# AT32F403Axx_v2 register map
Vendor: Keil; Series: AT32F403A; File version: 1.0
CPU: CM4 r0p1, little endian, no MPU, FPU, 4 interrupt priority bits
Registers are 32-bit, read-write, reset 0x0 unless marked. A register's access mark holds for its fields unless they carry their own. Offsets are from the block's base; [hi:lo] are bit positions.

## SPI1 — Serial peripheral interface
Base 0x40013000
Same registers: SPI2 0x40003800, SPI3 0x40003C00, SPI4 0x40004000, I2S2_EXT 0x40016C00, I2S3_EXT 0x40017000
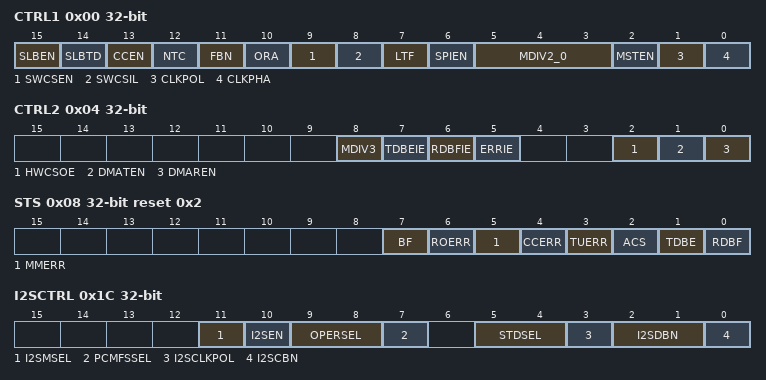
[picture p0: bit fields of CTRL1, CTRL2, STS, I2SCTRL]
0x00 CTRL1 — control register 1
  [15] SLBEN — Single line bidirectional half-duplex enable
  [14] SLBTD — Single line bidirectional half-duplex transmission direction
  [13] CCEN — CRC calculation enable
  [12] NTC — Next transmission CRC
  [11] FBN — frame bit num
  [10] ORA — Only receive active
  [9] SWCSEN — Software CS enable
  [8] SWCSIL — Software CS internal level
  [7] LTF — LSB transmit first
  [6] SPIEN — SPI enable
  [5:3] MDIV2_0 — Master clock frequency division bit2-0
  [2] MSTEN — Master enable
  [1] CLKPOL — Clock polarity
  [0] CLKPHA — Clock phase
0x04 CTRL2 — control register 2
  [8] MDIV3 — Master clock frequency division bit3
  [7] TDBEIE — Transmit data buffer empty interrupt enable
  [6] RDBFIE — Receive data buffer full interrupt enable
  [5] ERRIE — Error interrupt enable
  [2] HWCSOE — Hardware CS output enable
  [1] DMATEN — DMA transmit enable
  [0] DMAREN — DMA receive enable
0x08 STS reset 0x2 — status register
  [7] BF ro — Busy flag
  [6] ROERR ro — Receiver overflow error
  [5] MMERR ro — Master mode error
  [4] CCERR — CRC calculation error
  [3] TUERR ro — Transmitter underload error
  [2] ACS ro — Audio channel state
  [1] TDBE ro — Transmit data buffer empty
  [0] RDBF ro — Receive data buffer full
0x0C DT — data register
  [15:0] DT — Data value
0x10 CPOLY reset 0x7 — CRC polynomial register
  [15:0] CPOLY — CRC polynomial
0x14 RCRC ro — Receive CRC register
  [15:0] RCRC — Receive CRC
0x18 TCRC ro — Transmit CRC register
  [15:0] TCRC — Transmit CRC
0x1C I2SCTRL — I2S control register
  [11] I2SMSEL — I2S mode select
  [10] I2SEN — I2S Enable
  [9:8] OPERSEL — I2S operation select
  [7] PCMFSSEL — PCM frame synchronization select
  [5:4] STDSEL — I2S standard select
  [3] I2SCLKPOL — I2S clock polarity
  [2:1] I2SDBN — I2S data bit num
  [0] I2SCBN — I2S channel bit num
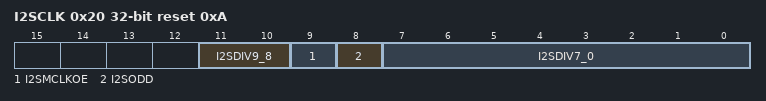
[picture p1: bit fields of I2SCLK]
0x20 I2SCLK reset 0xA — I2S clock register
  [11:10] I2SDIV9_8 — I2S division bit9 and bit8
  [9] I2SMCLKOE — I2S master clock output enable
  [8] I2SODD — Odd result for I2S division
  [7:0] I2SDIV7_0 — I2S division bit7 to bit0

## USART1 — Universal synchronous asynchronous receiver transmitter
Base 0x40013800
Same registers: USART2 0x40004400, USART3 0x40004800, UART4 0x40004C00, UART5 0x40005000, USART6 0x40016000, UART7 0x40016400, UART8 0x40016800
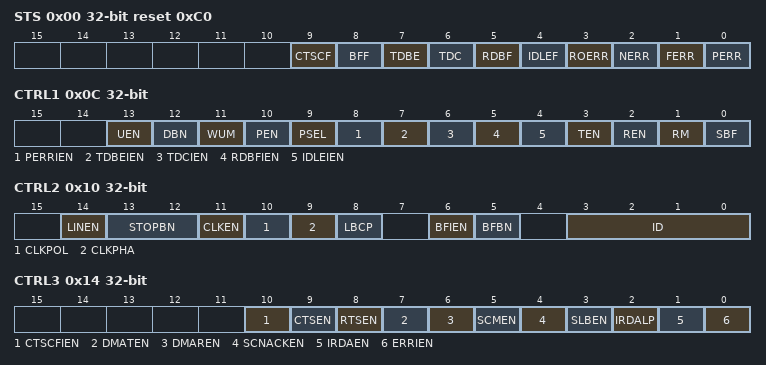
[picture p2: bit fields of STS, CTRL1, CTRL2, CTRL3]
0x00 STS reset 0xC0 — Status register
  [9] CTSCF — CTS change flag
  [8] BFF — Break frame flag
  [7] TDBE ro — Transmit data buffer empty
  [6] TDC — Transmit data complete
  [5] RDBF — Receive data buffer full
  [4] IDLEF ro — IDLE flag
  [3] ROERR ro — Receiver overflow error
  [2] NERR ro — Noise error
  [1] FERR ro — Framing error
  [0] PERR ro — Parity error
0x04 DT — Data register
  [8:0] DT — Data value
0x08 BAUDR — Baud rate register
  [15:0] DIV — Division
0x0C CTRL1 — Control register 1
  [13] UEN — USART enable
  [12] DBN — Data bit num
  [11] WUM — Wake up mode
  [10] PEN — Parity enable
  [9] PSEL — Parity selection
  [8] PERRIEN — PERR interrupt enable
  [7] TDBEIEN — TDBE interrupt enable
  [6] TDCIEN — TDC interrupt enable
  [5] RDBFIEN — RDBF interrupt enable
  [4] IDLEIEN — IDLE interrupt enable
  [3] TEN — Transmitter enable
  [2] REN — Receiver enable
  [1] RM — Receiver mute
  [0] SBF — Send break frame
0x10 CTRL2 — Control register 2
  [14] LINEN — LIN mode enable
  [13:12] STOPBN — STOP bit num
  [11] CLKEN — Clock enable
  [10] CLKPOL — Clock polarity
  [9] CLKPHA — Clock phase
  [8] LBCP — Last bit clock pulse
  [6] BFIEN — Break frame interrupt enable
  [5] BFBN — Break frame bit num
  [3:0] ID — USART identification
0x14 CTRL3 — Control register 3
  [10] CTSCFIEN — CTSCF interrupt enable
  [9] CTSEN — CTS enable
  [8] RTSEN — RTS enable
  [7] DMATEN — DMA transmitter enable
  [6] DMAREN — DMA receiver enable
  [5] SCMEN — Smartcard mode enable
  [4] SCNACKEN — Smartcard NACK enable
  [3] SLBEN — Single line bidirectional half-duplex enable
  [2] IRDALP — IrDA low-power mode
  [1] IRDAEN — IrDA enable
  [0] ERRIEN — Error interrupt enable
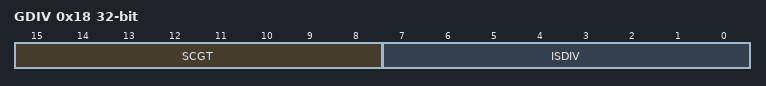
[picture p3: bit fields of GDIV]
0x18 GDIV — Guard time and division register
  [15:8] SCGT — Smart card guard time value
  [7:0] ISDIV — IrDA/smartcard division value
